VERSION ""

NS_ :

BS_:

BU_: RADAR XXX

BO_ 640 RADAR_TRACK_00: 64 RADAR
 SG_ CHECKSUM : 0|8@1+ (1,0) [0|255] "" XXX
 SG_ COUNTER : 8|4@1+ (1,0) [0|15] "" XXX
 SG_ TRACK_ID : 16|8@1+ (1,0) [0|255] "" XXX
 SG_ LEAD_VALID_COUNTER : 39|24@0+ (1,0) [0|16777215] "" XXX
 SG_ LONG_DIST_ALT : 71|16@0+ (0.01,0) [0|65535] "m" XXX
 SG_ LAT_DIST_ALT : 80|15@0- (0.01,0) [0|32767] "m" XXX
 SG_ VALID_COUNTER : 159|11@0+ (1,0) [0|2047] "" XXX
 SG_ UNKNOWN : 164|16@0- (1,0) [0|65535] "" XXX
 SG_ LONG_DIST : 194|16@0+ (0.01,0) [0|65535] "m" XXX
 SG_ LAT_DIST : 210|15@0- (0.01,0) [0|32767] "m" XXX
 SG_ CHECKSUM_2 : 256|8@1+ (1,0) [0|255] "" XXX
 SG_ COUNTER_2 : 264|4@1+ (1,0) [0|15] "" XXX
 SG_ CONFIDENCE : 273|25@0+ (2.98023233e-8,0) [0|33554431] "" XXX
 SG_ ALEAD : 365|13@0- (0.01,0) [0|8191] "ms-2" XXX
 SG_ VLEAD : 368|15@0- (0.01,0) [0|32767] "ms-1" XXX
 SG_ LAT_RELATED : 413|15@0- (0.01,0) [0|32767] "" XXX

BO_ 641 RADAR_TRACK_01: 64 RADAR
 SG_ CHECKSUM : 0|8@1+ (1,0) [0|255] "" XXX
 SG_ COUNTER : 8|4@1+ (1,0) [0|15] "" XXX
 SG_ TRACK_ID : 16|8@1+ (1,0) [0|255] "" XXX
 SG_ LEAD_VALID_COUNTER : 39|24@0+ (1,0) [0|16777215] "" XXX
 SG_ LONG_DIST_ALT : 71|16@0+ (0.01,0) [0|65535] "m" XXX
 SG_ LAT_DIST_ALT : 80|15@0- (0.01,0) [0|32767] "m" XXX
 SG_ VALID_COUNTER : 159|11@0+ (1,0) [0|2047] "" XXX
 SG_ UNKNOWN : 164|16@0- (1,0) [0|65535] "" XXX
 SG_ LONG_DIST : 194|16@0+ (0.01,0) [0|65535] "m" XXX
 SG_ LAT_DIST : 210|15@0- (0.01,0) [0|32767] "m" XXX
 SG_ CHECKSUM_2 : 256|8@1+ (1,0) [0|255] "" XXX
 SG_ COUNTER_2 : 264|4@1+ (1,0) [0|15] "" XXX
 SG_ CONFIDENCE : 273|25@0+ (2.98023233e-8,0) [0|33554431] "" XXX
 SG_ ALEAD : 365|13@0- (0.01,0) [0|8191] "ms-2" XXX
 SG_ VLEAD : 368|15@0- (0.01,0) [0|32767] "ms-1" XXX
 SG_ LAT_RELATED : 413|15@0- (0.01,0) [0|32767] "" XXX

BO_ 642 RADAR_TRACK_02: 64 RADAR
 SG_ CHECKSUM : 0|8@1+ (1,0) [0|255] "" XXX
 SG_ COUNTER : 8|4@1+ (1,0) [0|15] "" XXX
 SG_ TRACK_ID : 16|8@1+ (1,0) [0|255] "" XXX
 SG_ LEAD_VALID_COUNTER : 39|24@0+ (1,0) [0|16777215] "" XXX
 SG_ LONG_DIST_ALT : 71|16@0+ (0.01,0) [0|65535] "m" XXX
 SG_ LAT_DIST_ALT : 80|15@0- (0.01,0) [0|32767] "m" XXX
 SG_ VALID_COUNTER : 159|11@0+ (1,0) [0|2047] "" XXX
 SG_ UNKNOWN : 164|16@0- (1,0) [0|65535] "" XXX
 SG_ LONG_DIST : 194|16@0+ (0.01,0) [0|65535] "m" XXX
 SG_ LAT_DIST : 210|15@0- (0.01,0) [0|32767] "m" XXX
 SG_ CHECKSUM_2 : 256|8@1+ (1,0) [0|255] "" XXX
 SG_ COUNTER_2 : 264|4@1+ (1,0) [0|15] "" XXX
 SG_ CONFIDENCE : 273|25@0+ (2.98023233e-8,0) [0|33554431] "" XXX
 SG_ ALEAD : 365|13@0- (0.01,0) [0|8191] "ms-2" XXX
 SG_ VLEAD : 368|15@0- (0.01,0) [0|32767] "ms-1" XXX
 SG_ LAT_RELATED : 413|15@0- (0.01,0) [0|32767] "" XXX

BO_ 643 RADAR_TRACK_03: 64 RADAR
 SG_ CHECKSUM : 0|8@1+ (1,0) [0|255] "" XXX
 SG_ COUNTER : 8|4@1+ (1,0) [0|15] "" XXX
 SG_ TRACK_ID : 16|8@1+ (1,0) [0|255] "" XXX
 SG_ LEAD_VALID_COUNTER : 39|24@0+ (1,0) [0|16777215] "" XXX
 SG_ LONG_DIST_ALT : 71|16@0+ (0.01,0) [0|65535] "m" XXX
 SG_ LAT_DIST_ALT : 80|15@0- (0.01,0) [0|32767] "m" XXX
 SG_ VALID_COUNTER : 159|11@0+ (1,0) [0|2047] "" XXX
 SG_ UNKNOWN : 164|16@0- (1,0) [0|65535] "" XXX
 SG_ LONG_DIST : 194|16@0+ (0.01,0) [0|65535] "m" XXX
 SG_ LAT_DIST : 210|15@0- (0.01,0) [0|32767] "m" XXX
 SG_ CHECKSUM_2 : 256|8@1+ (1,0) [0|255] "" XXX
 SG_ COUNTER_2 : 264|4@1+ (1,0) [0|15] "" XXX
 SG_ CONFIDENCE : 273|25@0+ (2.98023233e-8,0) [0|33554431] "" XXX
 SG_ ALEAD : 365|13@0- (0.01,0) [0|8191] "ms-2" XXX
 SG_ VLEAD : 368|15@0- (0.01,0) [0|32767] "ms-1" XXX
 SG_ LAT_RELATED : 413|15@0- (0.01,0) [0|32767] "" XXX

BO_ 644 RADAR_TRACK_04: 64 RADAR
 SG_ CHECKSUM : 0|8@1+ (1,0) [0|255] "" XXX
 SG_ COUNTER : 8|4@1+ (1,0) [0|15] "" XXX
 SG_ TRACK_ID : 16|8@1+ (1,0) [0|255] "" XXX
 SG_ LEAD_VALID_COUNTER : 39|24@0+ (1,0) [0|16777215] "" XXX
 SG_ LONG_DIST_ALT : 71|16@0+ (0.01,0) [0|65535] "m" XXX
 SG_ LAT_DIST_ALT : 80|15@0- (0.01,0) [0|32767] "m" XXX
 SG_ VALID_COUNTER : 159|11@0+ (1,0) [0|2047] "" XXX
 SG_ UNKNOWN : 164|16@0- (1,0) [0|65535] "" XXX
 SG_ LONG_DIST : 194|16@0+ (0.01,0) [0|65535] "m" XXX
 SG_ LAT_DIST : 210|15@0- (0.01,0) [0|32767] "m" XXX
 SG_ CHECKSUM_2 : 256|8@1+ (1,0) [0|255] "" XXX
 SG_ COUNTER_2 : 264|4@1+ (1,0) [0|15] "" XXX
 SG_ CONFIDENCE : 273|25@0+ (2.98023233e-8,0) [0|33554431] "" XXX
 SG_ ALEAD : 365|13@0- (0.01,0) [0|8191] "ms-2" XXX
 SG_ VLEAD : 368|15@0- (0.01,0) [0|32767] "ms-1" XXX
 SG_ LAT_RELATED : 413|15@0- (0.01,0) [0|32767] "" XXX

BO_ 645 RADAR_TRACK_05: 64 RADAR
 SG_ CHECKSUM : 0|8@1+ (1,0) [0|255] "" XXX
 SG_ COUNTER : 8|4@1+ (1,0) [0|15] "" XXX
 SG_ TRACK_ID : 16|8@1+ (1,0) [0|255] "" XXX
 SG_ LEAD_VALID_COUNTER : 39|24@0+ (1,0) [0|16777215] "" XXX
 SG_ LONG_DIST_ALT : 71|16@0+ (0.01,0) [0|65535] "m" XXX
 SG_ LAT_DIST_ALT : 80|15@0- (0.01,0) [0|32767] "m" XXX
 SG_ VALID_COUNTER : 159|11@0+ (1,0) [0|2047] "" XXX
 SG_ UNKNOWN : 164|16@0- (1,0) [0|65535] "" XXX
 SG_ LONG_DIST : 194|16@0+ (0.01,0) [0|65535] "m" XXX
 SG_ LAT_DIST : 210|15@0- (0.01,0) [0|32767] "m" XXX
 SG_ CHECKSUM_2 : 256|8@1+ (1,0) [0|255] "" XXX
 SG_ COUNTER_2 : 264|4@1+ (1,0) [0|15] "" XXX
 SG_ CONFIDENCE : 273|25@0+ (2.98023233e-8,0) [0|33554431] "" XXX
 SG_ ALEAD : 365|13@0- (0.01,0) [0|8191] "ms-2" XXX
 SG_ VLEAD : 368|15@0- (0.01,0) [0|32767] "ms-1" XXX
 SG_ LAT_RELATED : 413|15@0- (0.01,0) [0|32767] "" XXX

BO_ 646 RADAR_TRACK_06: 64 RADAR
 SG_ CHECKSUM : 0|8@1+ (1,0) [0|255] "" XXX
 SG_ COUNTER : 8|4@1+ (1,0) [0|15] "" XXX
 SG_ TRACK_ID : 16|8@1+ (1,0) [0|255] "" XXX
 SG_ LEAD_VALID_COUNTER : 39|24@0+ (1,0) [0|16777215] "" XXX
 SG_ LONG_DIST_ALT : 71|16@0+ (0.01,0) [0|65535] "m" XXX
 SG_ LAT_DIST_ALT : 80|15@0- (0.01,0) [0|32767] "m" XXX
 SG_ VALID_COUNTER : 159|11@0+ (1,0) [0|2047] "" XXX
 SG_ UNKNOWN : 164|16@0- (1,0) [0|65535] "" XXX
 SG_ LONG_DIST : 194|16@0+ (0.01,0) [0|65535] "m" XXX
 SG_ LAT_DIST : 210|15@0- (0.01,0) [0|32767] "m" XXX
 SG_ CHECKSUM_2 : 256|8@1+ (1,0) [0|255] "" XXX
 SG_ COUNTER_2 : 264|4@1+ (1,0) [0|15] "" XXX
 SG_ CONFIDENCE : 273|25@0+ (2.98023233e-8,0) [0|33554431] "" XXX
 SG_ ALEAD : 365|13@0- (0.01,0) [0|8191] "ms-2" XXX
 SG_ VLEAD : 368|15@0- (0.01,0) [0|32767] "ms-1" XXX
 SG_ LAT_RELATED : 413|15@0- (0.01,0) [0|32767] "" XXX

BO_ 647 RADAR_TRACK_07: 64 RADAR
 SG_ CHECKSUM : 0|8@1+ (1,0) [0|255] "" XXX
 SG_ COUNTER : 8|4@1+ (1,0) [0|15] "" XXX
 SG_ TRACK_ID : 16|8@1+ (1,0) [0|255] "" XXX
 SG_ LEAD_VALID_COUNTER : 39|24@0+ (1,0) [0|16777215] "" XXX
 SG_ LONG_DIST_ALT : 71|16@0+ (0.01,0) [0|65535] "m" XXX
 SG_ LAT_DIST_ALT : 80|15@0- (0.01,0) [0|32767] "m" XXX
 SG_ VALID_COUNTER : 159|11@0+ (1,0) [0|2047] "" XXX
 SG_ UNKNOWN : 164|16@0- (1,0) [0|65535] "" XXX
 SG_ LONG_DIST : 194|16@0+ (0.01,0) [0|65535] "m" XXX
 SG_ LAT_DIST : 210|15@0- (0.01,0) [0|32767] "m" XXX
 SG_ CHECKSUM_2 : 256|8@1+ (1,0) [0|255] "" XXX
 SG_ COUNTER_2 : 264|4@1+ (1,0) [0|15] "" XXX
 SG_ CONFIDENCE : 273|25@0+ (2.98023233e-8,0) [0|33554431] "" XXX
 SG_ ALEAD : 365|13@0- (0.01,0) [0|8191] "ms-2" XXX
 SG_ VLEAD : 368|15@0- (0.01,0) [0|32767] "ms-1" XXX
 SG_ LAT_RELATED : 413|15@0- (0.01,0) [0|32767] "" XXX

BO_ 648 RADAR_TRACK_08: 64 RADAR
 SG_ CHECKSUM : 0|8@1+ (1,0) [0|255] "" XXX
 SG_ COUNTER : 8|4@1+ (1,0) [0|15] "" XXX
 SG_ TRACK_ID : 16|8@1+ (1,0) [0|255] "" XXX
 SG_ LEAD_VALID_COUNTER : 39|24@0+ (1,0) [0|16777215] "" XXX
 SG_ LONG_DIST_ALT : 71|16@0+ (0.01,0) [0|65535] "m" XXX
 SG_ LAT_DIST_ALT : 80|15@0- (0.01,0) [0|32767] "m" XXX
 SG_ VALID_COUNTER : 159|11@0+ (1,0) [0|2047] "" XXX
 SG_ UNKNOWN : 164|16@0- (1,0) [0|65535] "" XXX
 SG_ LONG_DIST : 194|16@0+ (0.01,0) [0|65535] "m" XXX
 SG_ LAT_DIST : 210|15@0- (0.01,0) [0|32767] "m" XXX
 SG_ CHECKSUM_2 : 256|8@1+ (1,0) [0|255] "" XXX
 SG_ COUNTER_2 : 264|4@1+ (1,0) [0|15] "" XXX
 SG_ CONFIDENCE : 273|25@0+ (2.98023233e-8,0) [0|33554431] "" XXX
 SG_ ALEAD : 365|13@0- (0.01,0) [0|8191] "ms-2" XXX
 SG_ VLEAD : 368|15@0- (0.01,0) [0|32767] "ms-1" XXX
 SG_ LAT_RELATED : 413|15@0- (0.01,0) [0|32767] "" XXX

BO_ 649 RADAR_TRACK_09: 64 RADAR
 SG_ CHECKSUM : 0|8@1+ (1,0) [0|255] "" XXX
 SG_ COUNTER : 8|4@1+ (1,0) [0|15] "" XXX
 SG_ TRACK_ID : 16|8@1+ (1,0) [0|255] "" XXX
 SG_ LEAD_VALID_COUNTER : 39|24@0+ (1,0) [0|16777215] "" XXX
 SG_ LONG_DIST_ALT : 71|16@0+ (0.01,0) [0|65535] "m" XXX
 SG_ LAT_DIST_ALT : 80|15@0- (0.01,0) [0|32767] "m" XXX
 SG_ VALID_COUNTER : 159|11@0+ (1,0) [0|2047] "" XXX
 SG_ UNKNOWN : 164|16@0- (1,0) [0|65535] "" XXX
 SG_ LONG_DIST : 194|16@0+ (0.01,0) [0|65535] "m" XXX
 SG_ LAT_DIST : 210|15@0- (0.01,0) [0|32767] "m" XXX
 SG_ CHECKSUM_2 : 256|8@1+ (1,0) [0|255] "" XXX
 SG_ COUNTER_2 : 264|4@1+ (1,0) [0|15] "" XXX
 SG_ CONFIDENCE : 273|25@0+ (2.98023233e-8,0) [0|33554431] "" XXX
 SG_ ALEAD : 365|13@0- (0.01,0) [0|8191] "ms-2" XXX
 SG_ VLEAD : 368|15@0- (0.01,0) [0|32767] "ms-1" XXX
 SG_ LAT_RELATED : 413|15@0- (0.01,0) [0|32767] "" XXX

BO_ 269 ECM: 8 XXX
 SG_ ENG_RPM : 0|16@1+ (0.25,0) [0|255] "" XXX
 SG_ GAS_PEDAL : 40|8@1+ (0.00392,0) [0|255] "" XXX

BO_ 289 ESC: 8 XXX
 SG_ VEHICLE_SPEED : 0|12@1+ (0.0725,0) [0|4095] "" XXX

BO_ 291 IPB: 8 XXX
 SG_ BRAKE_PRESSED : 43|1@0+ (1,0) [0|1] "" XXX

BO_ 301 BRAKE_PRESSED: 8 XXX
 SG_ BRAKE_PRESSED : 8|1@1+ (1,0) [0|1] "" XXX

BO_ 522 ENGINE_RPM: 8 XXX
 SG_ ENG_RPM : 31|8@0+ (1,0) [0|255] "" XXX

BO_ 523 ENGINE_GAUGE: 8 XXX
 SG_ ENG_RPM : 15|8@0+ (12,0) [0|0] "" XXX

BO_ 546 YAW_SENSOR: 8 XXX
 SG_ YAW_RATE : 0|12@1+ (0.002132603,-2.094216146) [0|4095] "" XXX
 SG_ YAW_OFFSET : 12|12@1+ (0.002132603,-0.130088783) [0|4095] "" XXX

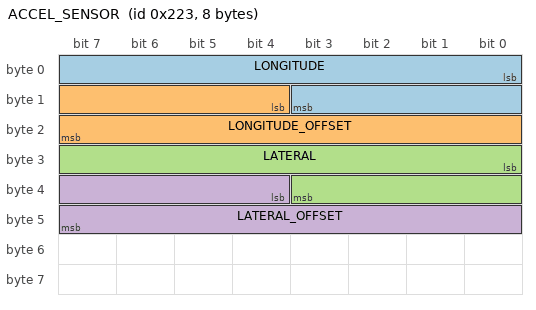
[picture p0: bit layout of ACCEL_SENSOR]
BO_ 547 ACCEL_SENSOR: 8 XXX
 SG_ LONGITUDE : 0|12@1- (0.027126736,-21.592881856) [-2848|1247] "" XXX
 SG_ LONGITUDE_OFFSET : 12|12@1+ (0.027126736,-21.592881856) [0|4095] "" XXX
 SG_ LATERAL : 24|12@1- (0.027126736,-21.592881856) [-2848|1247] "" XXX
 SG_ LATERAL_OFFSET : 36|12@1+ (0.027126736,-21.592881856) [0|4095] "" XXX

BO_ 926 GAUGE_SPEED: 8 XXX
 SG_ GAUGE_SPEED : 8|8@1+ (1,0) [0|255] "" XXX

CM_ "Imported from tembikaipilot (martinl byd-sealion-7 lineage). Two unrelated groups in one file, mirroring tembikai's split DBC: RADAR_TRACK_00..09 (0x280-0x289) are 64-byte CAN-FD perception tracks from the Veoneer MVS4 on the PRIVATE bus (FD-capable silicon required); the classic 8-byte chassis sensor frames (ESC/IPB/brake/RPM/yaw/accel/gauge) live on the CHASSIS bus. None are on-car validated against our captures yet - treat scaling and bit positions as tembikai's claims until arbitrated.";
